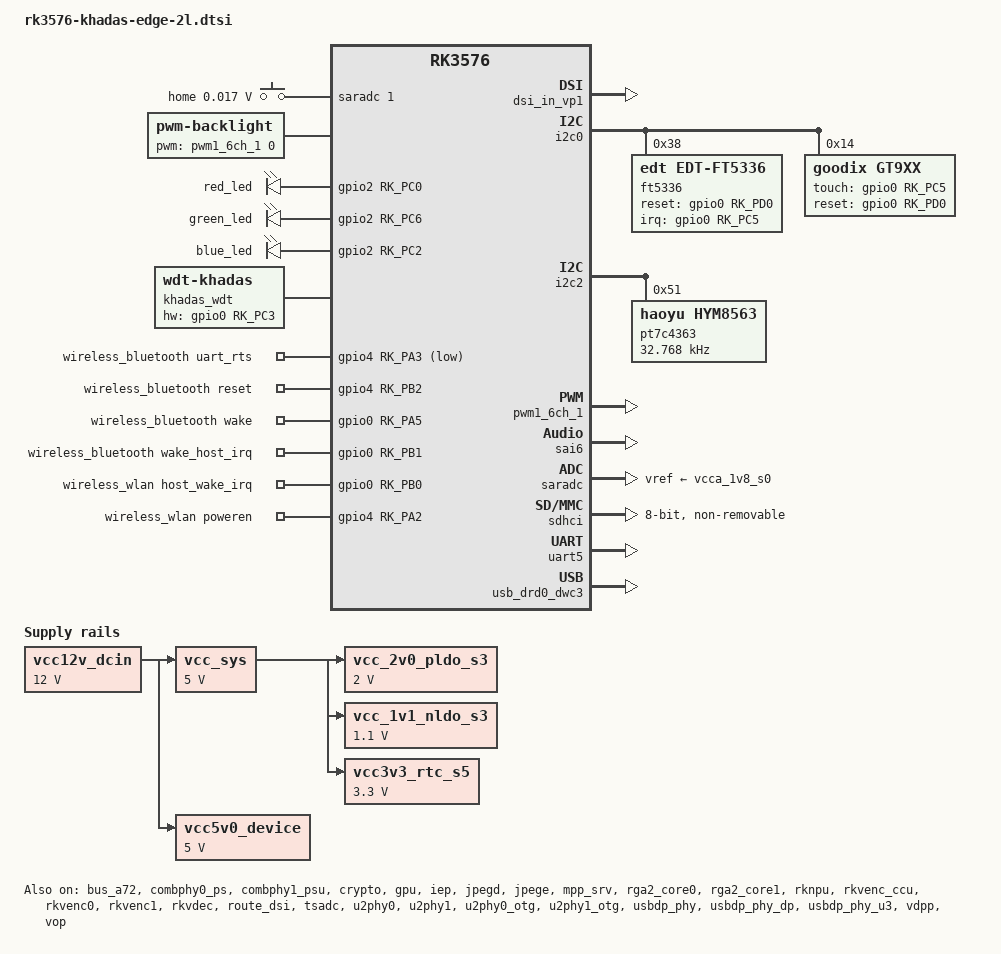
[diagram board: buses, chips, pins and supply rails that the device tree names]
// SPDX-License-Identifier: (GPL-2.0+ OR MIT)
/*
 * Copyright (c) 2024 Rockchip Electronics Co., Ltd.
 *
 */

#include <dt-bindings/gpio/gpio.h>
#include <dt-bindings/pwm/pwm.h>
#include <dt-bindings/pinctrl/rockchip.h>
#include <dt-bindings/input/rk-input.h>
#include <dt-bindings/display/drm_mipi_dsi.h>
#include <dt-bindings/display/rockchip_vop.h>
#include <dt-bindings/sensor-dev.h>
#include "rk3576-evb-input-keymap.dtsi"

/ {
	adc_keys: adc-keys {
		compatible = "adc-keys";
		io-channels = <&saradc 1>;
		io-channel-names = "buttons";
		keyup-threshold-microvolt = <1800000>;
		poll-interval = <100>;

		home-key {
			label = "home";
			linux,code = <KEY_HOMEPAGE>;
			press-threshold-microvolt = <17000>;
		};
	};

	backlight: backlight {
		compatible = "pwm-backlight";
		pwms = <&pwm1_6ch_1 0 25000 0>;
		brightness-levels = <
			  0  20  20  21  21  22  22  23
			 23  24  24  25  25  26  26  27
			 27  28  28  29  29  30  30  31
			 31  32  32  33  33  34  34  35
			 35  36  36  37  37  38  38  39
			 40  41  42  43  44  45  46  47
			 48  49  50  51  52  53  54  55
			 56  57  58  59  60  61  62  63
			 64  65  66  67  68  69  70  71
			 72  73  74  75  76  77  78  79
			 80  81  82  83  84  85  86  87
			 88  89  90  91  92  93  94  95
			 96  97  98  99 100 101 102 103
			104 105 106 107 108 109 110 111
			112 113 114 115 116 117 118 119
			120 121 122 123 124 125 126 127
			128 129 130 131 132 133 134 135
			136 137 138 139 140 141 142 143
			144 145 146 147 148 149 150 151
			152 153 154 155 156 157 158 159
			160 161 162 163 164 165 166 167
			168 169 170 171 172 173 174 175
			176 177 178 179 180 181 182 183
			184 185 186 187 188 189 190 191
			192 193 194 195 196 197 198 199
			200 201 202 203 204 205 206 207
			208 209 210 211 212 213 214 215
			216 217 218 219 220 221 222 223
			224 225 226 227 228 229 230 231
			232 233 234 235 236 237 238 239
			240 241 242 243 244 245 246 247
			248 249 250 251 252 253 254 255
		>;
		default-brightness-level = <200>;
	};

	dp0_sound: dp0-sound {
		status = "disabled";
		compatible = "rockchip,hdmi";
		rockchip,mclk-fs = <512>;
		rockchip,card-name = "rockchip-dp0";
		rockchip,cpu = <&spdif_tx3>;
		rockchip,codec = <&dp0 1>;
		rockchip,jack-det;
	};

	dp1_sound: dp1-sound {
		status = "disabled";
		compatible = "rockchip,hdmi";
		rockchip,mclk-fs = <512>;
		rockchip,card-name = "rockchip-dp1";
		rockchip,cpu = <&spdif_tx3>;
		rockchip,codec = <&dp1 1>;
		rockchip,jack-det;
	};

	dp2_sound: dp2-sound {
		status = "disabled";
		compatible = "rockchip,hdmi";
		rockchip,mclk-fs = <512>;
		rockchip,card-name = "rockchip-dp2";
		rockchip,cpu = <&spdif_tx3>;
		rockchip,codec = <&dp2 1>;
		rockchip,jack-det;
	};

	edp_sound: edp-sound {
		status = "disabled";
		compatible = "rockchip,hdmi";
		rockchip,mclk-fs = <128>;
		rockchip,card-name = "rockchip-edp";
		rockchip,cpu = <&sai6>;
		rockchip,codec = <&edp 0>;
	};

	hdmi_sound: hdmi-sound {
		compatible = "rockchip,hdmi";
		rockchip,mclk-fs = <128>;
		rockchip,card-name = "rockchip-hdmi";
		rockchip,cpu = <&sai6>;
		rockchip,codec = <&hdmi>;
		rockchip,jack-det;
	};

	leds {
		compatible = "gpio-leds";
		pinctrl-names = "default";

		red_led {
			gpios = <&gpio2 RK_PC0 GPIO_ACTIVE_HIGH>;
			label = "red_led";
			linux,default-trigger = "off";
			default-state = "on";
		};

		green_led {
			gpios = <&gpio2 RK_PC6 GPIO_ACTIVE_HIGH>;
			label = "green_led";
			linux,default-trigger = "off";
			default-state = "on";
		};

		blue_led {
			gpios = <&gpio2 RK_PC2 GPIO_ACTIVE_HIGH>;
			label = "blue_led";
			linux,default-trigger = "default-on";
			default-state = "on";
		};
	};

	khadas_wdt {
		compatible = "linux,wdt-khadas";
		status = "okay";
		hw_margin_ms = <500>;
		hw-gpios = <&gpio0 RK_PC3 GPIO_ACTIVE_HIGH>;
		pinctrl-names = "default";
		pinctrl-0 = <&wdt_gpio>;
	};

	test-power {
		status = "okay";
	};

	vcc12v_dcin: vcc12v-dcin {
		compatible = "regulator-fixed";
		regulator-name = "vcc12v_dcin";
		regulator-always-on;
		regulator-boot-on;
		regulator-min-microvolt = <12000000>;
		regulator-max-microvolt = <12000000>;
	};

	vcc_sys: vcc5v0-sys {
		compatible = "regulator-fixed";
		regulator-name = "vcc_sys";
		regulator-always-on;
		regulator-boot-on;
		regulator-min-microvolt = <5000000>;
		regulator-max-microvolt = <5000000>;
		vin-supply = <&vcc12v_dcin>;
	};

	vcc5v0_device: vcc5v0-device {
		compatible = "regulator-fixed";
		regulator-name = "vcc5v0_device";
		regulator-always-on;
		regulator-boot-on;
		regulator-min-microvolt = <5000000>;
		regulator-max-microvolt = <5000000>;
		vin-supply = <&vcc12v_dcin>;
	};

	vcc_2v0_pldo_s3: vcc-2v0-pldo-s3 {
		compatible = "regulator-fixed";
		regulator-name = "vcc_2v0_pldo_s3";
		regulator-boot-on;
		regulator-always-on;
		regulator-min-microvolt = <2000000>;
		regulator-max-microvolt = <2000000>;
		vin-supply = <&vcc_sys>;
	};

	vcc_1v1_nldo_s3: vcc-1v1-nldo-s3 {
		compatible = "regulator-fixed";
		regulator-name = "vcc_1v1_nldo_s3";
		regulator-boot-on;
		regulator-always-on;
		regulator-min-microvolt = <1100000>;
		regulator-max-microvolt = <1100000>;
		vin-supply = <&vcc_sys>;
	};

	vcc3v3_rtc_s5: vcc3v3-rtc-s5 {
		compatible = "regulator-fixed";
		regulator-name = "vcc3v3_rtc_s5";
		regulator-boot-on;
		regulator-always-on;
		regulator-min-microvolt = <3300000>;
		regulator-max-microvolt = <3300000>;
		vin-supply = <&vcc_sys>;
	};

	wireless_bluetooth: wireless-bluetooth {
		compatible = "bluetooth-platdata";
		uart_rts_gpios = <&gpio4 RK_PA3 GPIO_ACTIVE_LOW>;
		pinctrl-names = "default", "rts_gpio";
		pinctrl-0 = <&uart5m1_rtsn>, <&bt_gpio>;
		pinctrl-1 = <&uart5_gpios>;
		BT,reset_gpio    = <&gpio4 RK_PB2 GPIO_ACTIVE_HIGH>;
		BT,wake_gpio     = <&gpio0 RK_PA5 GPIO_ACTIVE_HIGH>;
		BT,wake_host_irq = <&gpio0 RK_PB1 GPIO_ACTIVE_HIGH>;
		status = "okay";
	};

	wireless_wlan: wireless-wlan {
		compatible = "wlan-platdata";
		wifi_chip_type = "ap6275p";
		pinctrl-names = "default";
		pinctrl-0 = <&wifi_host_wake_irq>, <&wifi_poweren_gpio>;
		WIFI,host_wake_irq = <&gpio0 RK_PB0 GPIO_ACTIVE_HIGH>;
		WIFI,poweren_gpio = <&gpio4 RK_PA2 GPIO_ACTIVE_HIGH>;
		status = "okay";
	};
};

&bus_a72 {
	bus-supply = <&vdd_logic_s0>;
	pvtm-supply = <&vdd_logic_s0>;
	status = "okay";
};

&combphy0_ps {
	status = "okay";
};

&combphy1_psu {
	status = "okay";
};

&cpu_l0 {
	cpu-supply = <&vdd_cpu_lit_s0>;
};

&cpu_b0 {
	cpu-supply = <&vdd_cpu_big_s0>;
};

&crypto {
	status = "okay";
};

&display_subsystem {
	clocks = <&hdptxphy_hdmi>;
	clock-names = "hdmi0_phy_pll";
};

&dsi {
	status = "disabled";
	//rockchip,lane-rate = <1000>;
	dsi_panel: panel@0 {
		status = "okay";
		compatible = "simple-panel-dsi";
		reg = <0>;
		backlight = <&backlight>;
		reset-delay-ms = <10>;
		enable-delay-ms = <10>;
		prepare-delay-ms = <10>;
		unprepare-delay-ms = <10>;
		disable-delay-ms = <60>;
		width-mm = <68>;
		height-mm = <121>;
		dsi,flags = <(MIPI_DSI_MODE_VIDEO | MIPI_DSI_MODE_VIDEO_BURST |
			      MIPI_DSI_MODE_LPM | MIPI_DSI_MODE_NO_EOT_PACKET)>;
		dsi,format = <MIPI_DSI_FMT_RGB888>;
		dsi,lanes  = <4>;
		panel-init-sequence = [
			15 00 02 FF 05
			15 00 02 FB 01
			15 64 02 C5 01
			15 00 02 FF EE
			15 00 02 FB 01
			15 00 02 1F 45
			15 00 02 24 4F
			15 00 02 38 C8
			15 00 02 39 27
			15 00 02 1E 77
			15 00 02 1D 0F
			15 00 02 7E 71
			15 00 02 7C 03
			15 00 02 FF 00
			15 00 02 FB 01
			15 00 02 35 01
			15 00 02 FF 01
			15 00 02 FB 01
			15 00 02 00 01
			15 00 02 01 55
			15 00 02 02 40
			15 00 02 05 40
			15 00 02 06 4A
			15 00 02 07 24
			15 00 02 08 0C
			15 00 02 0B 7D
			15 00 02 0C 7D
			15 00 02 0E B0
			15 00 02 0F AE
			15 00 02 11 10
			15 00 02 12 10
			15 00 02 13 03
			15 00 02 14 4A
			15 00 02 15 12
			15 00 02 16 12
			15 00 02 18 00
			15 00 02 19 77
			15 00 02 1A 55
			15 00 02 1B 13
			15 00 02 1C 00
			15 00 02 1D 00
			15 00 02 1E 13
			15 00 02 1F 00
			15 00 02 23 00
			15 00 02 24 00
			15 00 02 25 00
			15 00 02 26 00
			15 00 02 27 00
			15 00 02 28 00
			15 00 02 35 00
			15 00 02 66 00
			15 00 02 58 82
			15 00 02 59 02
			15 00 02 5A 02
			15 00 02 5B 02
			15 00 02 5C 82
			15 00 02 5D 82
			15 00 02 5E 02
			15 00 02 5F 02
			15 00 02 72 31
			15 00 02 FF 05
			15 00 02 FB 01
			15 00 02 00 01
			15 00 02 01 0B
			15 00 02 02 0C
			15 00 02 03 09
			15 00 02 04 0A
			15 00 02 05 00
			15 00 02 06 0F
			15 00 02 07 10
			15 00 02 08 00
			15 00 02 09 00
			15 00 02 0A 00
			15 00 02 0B 00
			15 00 02 0C 00
			15 00 02 0D 13
			15 00 02 0E 15
			15 00 02 0F 17
			15 00 02 10 01
			15 00 02 11 0B
			15 00 02 12 0C
			15 00 02 13 09
			15 00 02 14 0A
			15 00 02 15 00
			15 00 02 16 0F
			15 00 02 17 10
			15 00 02 18 00
			15 00 02 19 00
			15 00 02 1A 00
			15 00 02 1B 00
			15 00 02 1C 00
			15 00 02 1D 13
			15 00 02 1E 15
			15 00 02 1F 17
			15 00 02 20 00
			15 00 02 21 03
			15 00 02 22 01
			15 00 02 23 40
			15 00 02 24 40
			15 00 02 25 ED
			15 00 02 29 58
			15 00 02 2A 12
			15 00 02 2B 01
			15 00 02 4B 06
			15 00 02 4C 11
			15 00 02 4D 20
			15 00 02 4E 02
			15 00 02 4F 02
			15 00 02 50 20
			15 00 02 51 61
			15 00 02 52 01
			15 00 02 53 63
			15 00 02 54 77
			15 00 02 55 ED
			15 00 02 5B 00
			15 00 02 5C 00
			15 00 02 5D 00
			15 00 02 5E 00
			15 00 02 5F 15
			15 00 02 60 75
			15 00 02 61 00
			15 00 02 62 00
			15 00 02 63 00
			15 00 02 64 00
			15 00 02 65 00
			15 00 02 66 00
			15 00 02 67 00
			15 00 02 68 04
			15 00 02 69 00
			15 00 02 6A 00
			15 00 02 6C 40
			15 00 02 75 01
			15 00 02 76 01
			15 00 02 7A 80
			15 00 02 7B A3
			15 00 02 7C D8
			15 00 02 7D 60
			15 00 02 7F 15
			15 00 02 80 81
			15 00 02 83 05
			15 00 02 93 08
			15 00 02 94 10
			15 00 02 8A 00
			15 00 02 9B 0F
			15 00 02 EA FF
			15 00 02 EC 00
			15 00 02 FF 01
			15 00 02 FB 01
			15 00 02 75 00
			15 00 02 76 DF
			15 00 02 77 00
			15 00 02 78 E4
			15 00 02 79 00
			15 00 02 7A ED
			15 00 02 7B 00
			15 00 02 7C F6
			15 00 02 7D 00
			15 00 02 7E FF
			15 00 02 7F 01
			15 00 02 80 07
			15 00 02 81 01
			15 00 02 82 10
			15 00 02 83 01
			15 00 02 84 18
			15 00 02 85 01
			15 00 02 86 20
			15 00 02 87 01
			15 00 02 88 3D
			15 00 02 89 01
			15 00 02 8A 56
			15 00 02 8B 01
			15 00 02 8C 84
			15 00 02 8D 01
			15 00 02 8E AB
			15 00 02 8F 01
			15 00 02 90 EC
			15 00 02 91 02
			15 00 02 92 22
			15 00 02 93 02
			15 00 02 94 23
			15 00 02 95 02
			15 00 02 96 55
			15 00 02 97 02
			15 00 02 98 8B
			15 00 02 99 02
			15 00 02 9A AF
			15 00 02 9B 02
			15 00 02 9C DF
			15 00 02 9D 03
			15 00 02 9E 01
			15 00 02 9F 03
			15 00 02 A0 2C
			15 00 02 A2 03
			15 00 02 A3 39
			15 00 02 A4 03
			15 00 02 A5 47
			15 00 02 A6 03
			15 00 02 A7 56
			15 00 02 A9 03
			15 00 02 AA 66
			15 00 02 AB 03
			15 00 02 AC 76
			15 00 02 AD 03
			15 00 02 AE 85
			15 00 02 AF 03
			15 00 02 B0 90
			15 00 02 B1 03
			15 00 02 B2 CB
			15 00 02 B3 00
			15 00 02 B4 DF
			15 00 02 B5 00
			15 00 02 B6 E4
			15 00 02 B7 00
			15 00 02 B8 ED
			15 00 02 B9 00
			15 00 02 BA F6
			15 00 02 BB 00
			15 00 02 BC FF
			15 00 02 BD 01
			15 00 02 BE 07
			15 00 02 BF 01
			15 00 02 C0 10
			15 00 02 C1 01
			15 00 02 C2 18
			15 00 02 C3 01
			15 00 02 C4 20
			15 00 02 C5 01
			15 00 02 C6 3D
			15 00 02 C7 01
			15 00 02 C8 56
			15 00 02 C9 01
			15 00 02 CA 84
			15 00 02 CB 01
			15 00 02 CC AB
			15 00 02 CD 01
			15 00 02 CE EC
			15 00 02 CF 02
			15 00 02 D0 22
			15 00 02 D1 02
			15 00 02 D2 23
			15 00 02 D3 02
			15 00 02 D4 55
			15 00 02 D5 02
			15 00 02 D6 8B
			15 00 02 D7 02
			15 00 02 D8 AF
			15 00 02 D9 02
			15 00 02 DA DF
			15 00 02 DB 03
			15 00 02 DC 01
			15 00 02 DD 03
			15 00 02 DE 2C
			15 00 02 DF 03
			15 00 02 E0 39
			15 00 02 E1 03
			15 00 02 E2 47
			15 00 02 E3 03
			15 00 02 E4 56
			15 00 02 E5 03
			15 00 02 E6 66
			15 00 02 E7 03
			15 00 02 E8 76
			15 00 02 E9 03
			15 00 02 EA 85
			15 00 02 EB 03
			15 00 02 EC 90
			15 00 02 ED 03
			15 00 02 EE CB
			15 00 02 EF 00
			15 00 02 F0 BB
			15 00 02 F1 00
			15 00 02 F2 C0
			15 00 02 F3 00
			15 00 02 F4 CC
			15 00 02 F5 00
			15 00 02 F6 D6
			15 00 02 F7 00
			15 00 02 F8 E1
			15 00 02 F9 00
			15 00 02 FA EA
			15 00 02 FF 02
			15 00 02 FB 01
			15 00 02 00 00
			15 00 02 01 F4
			15 00 02 02 00
			15 00 02 03 EF
			15 00 02 04 01
			15 00 02 05 07
			15 00 02 06 01
			15 00 02 07 28
			15 00 02 08 01
			15 00 02 09 44
			15 00 02 0A 01
			15 00 02 0B 76
			15 00 02 0C 01
			15 00 02 0D A0
			15 00 02 0E 01
			15 00 02 0F E7
			15 00 02 10 02
			15 00 02 11 1F
			15 00 02 12 02
			15 00 02 13 22
			15 00 02 14 02
			15 00 02 15 54
			15 00 02 16 02
			15 00 02 17 8B
			15 00 02 18 02
			15 00 02 19 AF
			15 00 02 1A 02
			15 00 02 1B E0
			15 00 02 1C 03
			15 00 02 1D 01
			15 00 02 1E 03
			15 00 02 1F 2D
			15 00 02 20 03
			15 00 02 21 39
			15 00 02 22 03
			15 00 02 23 47
			15 00 02 24 03
			15 00 02 25 57
			15 00 02 26 03
			15 00 02 27 65
			15 00 02 28 03
			15 00 02 29 77
			15 00 02 2A 03
			15 00 02 2B 85
			15 00 02 2D 03
			15 00 02 2F 8F
			15 00 02 30 03
			15 00 02 31 CB
			15 00 02 32 00
			15 00 02 33 BB
			15 00 02 34 00
			15 00 02 35 C0
			15 00 02 36 00
			15 00 02 37 CC
			15 00 02 38 00
			15 00 02 39 D6
			15 00 02 3A 00
			15 00 02 3B E1
			15 00 02 3D 00
			15 00 02 3F EA
			15 00 02 40 00
			15 00 02 41 F4
			15 00 02 42 00
			15 00 02 43 FE
			15 00 02 44 01
			15 00 02 45 07
			15 00 02 46 01
			15 00 02 47 28
			15 00 02 48 01
			15 00 02 49 44
			15 00 02 4A 01
			15 00 02 4B 76
			15 00 02 4C 01
			15 00 02 4D A0
			15 00 02 4E 01
			15 00 02 4F E7
			15 00 02 50 02
			15 00 02 51 1F
			15 00 02 52 02
			15 00 02 53 22
			15 00 02 54 02
			15 00 02 55 54
			15 00 02 56 02
			15 00 02 58 8B
			15 00 02 59 02
			15 00 02 5A AF
			15 00 02 5B 02
			15 00 02 5C E0
			15 00 02 5D 03
			15 00 02 5E 01
			15 00 02 5F 03
			15 00 02 60 2D
			15 00 02 61 03
			15 00 02 62 39
			15 00 02 63 03
			15 00 02 64 47
			15 00 02 65 03
			15 00 02 66 57
			15 00 02 67 03
			15 00 02 68 65
			15 00 02 69 03
			15 00 02 6A 77
			15 00 02 6B 03
			15 00 02 6C 85
			15 00 02 6D 03
			15 00 02 6E 8F
			15 00 02 6F 03
			15 00 02 70 CB
			15 00 02 71 00
			15 00 02 72 00
			15 00 02 73 00
			15 00 02 74 21
			15 00 02 75 00
			15 00 02 76 4C
			15 00 02 77 00
			15 00 02 78 6B
			15 00 02 79 00
			15 00 02 7A 85
			15 00 02 7B 00
			15 00 02 7C 9A
			15 00 02 7D 00
			15 00 02 7E AD
			15 00 02 7F 00
			15 00 02 80 BE
			15 00 02 81 00
			15 00 02 82 CD
			15 00 02 83 01
			15 00 02 84 01
			15 00 02 85 01
			15 00 02 86 29
			15 00 02 87 01
			15 00 02 88 68
			15 00 02 89 01
			15 00 02 8A 98
			15 00 02 8B 01
			15 00 02 8C E5
			15 00 02 8D 02
			15 00 02 8E 1E
			15 00 02 8F 02
			15 00 02 90 30
			15 00 02 91 02
			15 00 02 92 52
			15 00 02 93 02
			15 00 02 94 88
			15 00 02 95 02
			15 00 02 96 AA
			15 00 02 97 02
			15 00 02 98 D7
			15 00 02 99 02
			15 00 02 9A F7
			15 00 02 9B 03
			15 00 02 9C 21
			15 00 02 9D 03
			15 00 02 9E 2E
			15 00 02 9F 03
			15 00 02 A0 3D
			15 00 02 A2 03
			15 00 02 A3 4C
			15 00 02 A4 03
			15 00 02 A5 5E
			15 00 02 A6 03
			15 00 02 A7 71
			15 00 02 A9 03
			15 00 02 AA 86
			15 00 02 AB 03
			15 00 02 AC 94
			15 00 02 AD 03
			15 00 02 AE FA
			15 00 02 AF 00
			15 00 02 B0 00
			15 00 02 B1 00
			15 00 02 B2 21
			15 00 02 B3 00
			15 00 02 B4 4C
			15 00 02 B5 00
			15 00 02 B6 6B
			15 00 02 B7 00
			15 00 02 B8 85
			15 00 02 B9 00
			15 00 02 BA 9A
			15 00 02 BB 00
			15 00 02 BC AD
			15 00 02 BD 00
			15 00 02 BE BE
			15 00 02 BF 00
			15 00 02 C0 CD
			15 00 02 C1 01
			15 00 02 C2 01
			15 00 02 C3 01
			15 00 02 C4 29
			15 00 02 C5 01
			15 00 02 C6 68
			15 00 02 C7 01
			15 00 02 C8 98
			15 00 02 C9 01
			15 00 02 CA E5
			15 00 02 CB 02
			15 00 02 CC 1E
			15 00 02 CD 02
			15 00 02 CE 20
			15 00 02 CF 02
			15 00 02 D0 52
			15 00 02 D1 02
			15 00 02 D2 88
			15 00 02 D3 02
			15 00 02 D4 AA
			15 00 02 D5 02
			15 00 02 D6 D7
			15 00 02 D7 02
			15 00 02 D8 F7
			15 00 02 D9 03
			15 00 02 DA 21
			15 00 02 DB 03
			15 00 02 DC 2E
			15 00 02 DD 03
			15 00 02 DE 3D
			15 00 02 DF 03
			15 00 02 E0 4C
			15 00 02 E1 03
			15 00 02 E2 5E
			15 00 02 E3 03
			15 00 02 E4 71
			15 00 02 E5 03
			15 00 02 E6 86
			15 00 02 E7 03
			15 00 02 E8 94
			15 00 02 E9 03
			15 00 02 EA FA
			15 00 02 FF 01
			15 00 02 FB 01
			15 00 02 FF 02
			15 00 02 FB 01
			15 00 02 FF 04
			15 00 02 FB 01
			15 00 02 FF 00
			15 00 02 D3 05
			15 00 02 D4 04
			05 78 01 11
			15 00 02 FF 00
			15 00 02 35 00
			05 0A 01 29
		];

		panel-init-sequence2 = [
			39 00 04 B9 FF 83 99
			39 00 05 BA 63 23 68 CF
			15 00 02 D2 55
			39 00 10 B1 02 04 70 90 01 32 33 11 11 4D 57 56 73 02 02
			39 00 0c B2 00 80 80 AE 0A 0E 75 11 00 00 00
			39 00 2f B4 00 FF 04 A4 02 A0 00 00 10 00 00 02 00 24 02 04 0A 21 03 00 00 08 A6 88 04 A4 02 A0 00 00 10 00 00 02 00 24 02 04 0A 00 00 08 A6 00 08 11
			39 00 22 D3 00 00 00 00 00 00 18 18 32 10 09 00 09 32 10 00 00 00 00 00 00 00 00 11 00 02 02 03 00 00 00 0A 40
			39 00 21 D5 18 18 18 18 21 20 18 18 19 19 19 19 18 18 18 18 03 02 01 00 2F 2F 30 30 31 31 18 18 18 18 18 18
			39 00 21 D6 18 18 18 18 20 21 19 19 18 18 19 19 18 18 18 18 00 01 02 03 2F 2F 30 30 31 31 18 18 18 18 18 18
			39 00 09 D8 0A BE FA A0 0A BE FA A0
			15 00 02 BD 01
			39 00 09 D8 0F FF FF E0 0F FF FF E0
			15 00 02 BD 02
			39 00 09 D8 0F FF FF E0 0F FF FF E0
			15 00 02 BD 00
			39 00 37 E0 01 35 41 3B 79 81 8C 85 8E 95 9B A0 A4 AB B1 B3 B7 C5 BD C5 B6 C2 C2 62 5D 66 73 01 35 41 3B 79 81 8C 85 8E 95 9B A0 A4 AB B1 B3 B7 B5 BD C5 B6 C2 C2 62 5D 66 73
			39 00 03 B6 97 97
			15 00 02 CC C8
			39 00 05 BF 40 41 50 19
			39 00 03 C6 FF F9
			39 00 03 C0 25 5A
			05 78 01 11
			05 14 01 29
		];

		panel-init-sequence3 = [
			15 00 02 B0 05
			15 00 02 C0 01
			15 00 02 C2 01
			15 00 02 D9 01
			15 00 02 DB 01
			15 00 02 B0 00
			15 00 02 B6 03
			15 00 02 BD 62
			15 00 02 C2 16
			15 00 02 C3 02
			15 00 02 C4 16
			15 00 02 C5 02
			15 00 02 B0 01
			15 00 02 E0 0F
			15 00 02 E1 0F
			15 00 02 DC 10
			15 00 02 DD 10
			15 00 02 CC 0F
			15 00 02 CD 0F
			15 00 02 C8 10
			15 00 02 C9 10
			15 00 02 B0 03
			15 00 02 C5 2C
			15 00 02 DE 2C
			15 00 02 CA 42
			15 00 02 D6 88
			15 00 02 D7 08
			15 00 02 D2 06
			15 00 02 D3 06
			15 00 02 B0 05
			15 00 02 B3 52
			15 00 02 BC 20
			15 00 02 B0 06
			15 00 02 B8 A5
			15 00 02 C0 A5
			15 00 02 C7 0F
			15 00 02 D5 32
			15 00 02 B0 02
			15 00 02 C0 00
			15 00 02 C1 14
			15 00 02 C2 16
			15 00 02 C3 24
			15 00 02 C4 25
			15 00 02 C5 31
			15 00 02 C6 2A
			15 00 02 C7 2D
			15 00 02 C8 33
			15 00 02 C9 37
			15 00 02 CA 3F
			15 00 02 CB 3F
			15 00 02 CC 3F
			15 00 02 CD 2D
			15 00 02 CE 2E
			15 00 02 CF 29
			15 00 02 D0 04
			15 00 02 D2 00
			15 00 02 D3 14
			15 00 02 D4 14
			15 00 02 D5 26
			15 00 02 D6 2D
			15 00 02 D7 31
			15 00 02 D8 38
			15 00 02 D9 3D
			15 00 02 DA 3F
			15 00 02 DB 3F
			15 00 02 DC 3F
			15 00 02 DD 3F
			15 00 02 DE 3F
			15 00 02 DF 38
			15 00 02 E0 35
			15 00 02 E1 2D
			15 00 02 E2 0A
			15 00 02 B0 06
			15 00 02 B8 A5
			15 00 02 BC 33
			15 00 02 B0 07
			15 00 02 B1 00
			15 00 02 B2 04
			15 00 02 B3 0D
			15 00 02 B4 31
			15 00 02 B5 4F
			15 00 02 B6 6F
			15 00 02 B7 A1
			15 00 02 B8 E5
			15 00 02 B9 5B
			15 00 02 BA C1
			15 00 02 BB 54
			15 00 02 BC BB
			15 00 02 BD BE
			15 00 02 BE 12
			15 00 02 BF 69
			15 00 02 C0 94
			15 00 02 C1 B6
			15 00 02 C2 C8
			15 00 02 C3 DB
			15 00 02 C4 E8
			15 00 02 C5 F3
			15 00 02 C6 F9
			15 00 02 C7 FB
			15 00 02 C8 FC
			15 00 02 C9 00
			15 00 02 CA 00
			15 00 02 CB 5A
			15 00 02 CC BF
			15 00 02 CD FF
			15 00 02 CE FF
			15 00 02 B0 08
			15 00 02 B1 00
			15 00 02 B2 04
			15 00 02 B3 0D
			15 00 02 B4 31
			15 00 02 B5 4F
			15 00 02 B6 6F
			15 00 02 B7 A1
			15 00 02 B8 E5
			15 00 02 B9 5B
			15 00 02 BA C1
			15 00 02 BB 54
			15 00 02 BC BB
			15 00 02 BD BE
			15 00 02 BE 12
			15 00 02 BF 69
			15 00 02 C0 94
			15 00 02 C1 B6
			15 00 02 C2 C8
			15 00 02 C3 DB
			15 00 02 C4 E8
			15 00 02 C5 F3
			15 00 02 C6 F9
			15 00 02 C7 FB
			15 00 02 C8 FC
			15 00 02 C9 00
			15 00 02 CA 00
			15 00 02 CB 5A
			15 00 02 CC BF
			15 00 02 CD FF
			15 00 02 CE FF
			15 00 02 B0 09
			15 00 02 B1 00
			15 00 02 B2 04
			15 00 02 B3 0D
			15 00 02 B4 31
			15 00 02 B5 4F
			15 00 02 B6 6F
			15 00 02 B7 A1
			15 00 02 B8 E5
			15 00 02 B9 5B
			15 00 02 BA C1
			15 00 02 BB 54
			15 00 02 BC BB
			15 00 02 BD BE
			15 00 02 BE 12
			15 00 02 BF 69
			15 00 02 C0 94
			15 00 02 C1 B6
			15 00 02 C2 C8
			15 00 02 C3 DB
			15 00 02 C4 E8
			15 00 02 C5 F3
			15 00 02 C6 F9
			15 00 02 C7 FB
			15 00 02 C8 FC
			15 00 02 C9 00
			15 00 02 CA 00
			15 00 02 CB 5A
			15 00 02 CC BF
			15 00 02 CD FF
			15 00 02 CE FF
			15 00 02 B0 0A
			15 00 02 B1 00
			15 00 02 B2 04
			15 00 02 B3 0D
			15 00 02 B4 31
			15 00 02 B5 4F
			15 00 02 B6 6F
			15 00 02 B7 A1
			15 00 02 B8 E5
			15 00 02 B9 5B
			15 00 02 BA C1
			15 00 02 BB 54
			15 00 02 BC BB
			15 00 02 BD BE
			15 00 02 BE 12
			15 00 02 BF 69
			15 00 02 C0 94
			15 00 02 C1 B6
			15 00 02 C2 C8
			15 00 02 C3 DB
			15 00 02 C4 E8
			15 00 02 C5 F3
			15 00 02 C6 F9
			15 00 02 C7 FB
			15 00 02 C8 FC
			15 00 02 C9 00
			15 00 02 CA 00
			15 00 02 CB 5A
			15 00 02 CC BF
			15 00 02 CD FF
			15 00 02 CE FF
			15 00 02 B0 0B
			15 00 02 B1 00
			15 00 02 B2 04
			15 00 02 B3 0D
			15 00 02 B4 31
			15 00 02 B5 4F
			15 00 02 B6 6F
			15 00 02 B7 A1
			15 00 02 B8 E5
			15 00 02 B9 5B
			15 00 02 BA C1
			15 00 02 BB 54
			15 00 02 BC BB
			15 00 02 BD BE
			15 00 02 BE 12
			15 00 02 BF 69
			15 00 02 C0 94
			15 00 02 C1 B6
			15 00 02 C2 C8
			15 00 02 C3 DB
			15 00 02 C4 E8
			15 00 02 C5 F3
			15 00 02 C6 F9
			15 00 02 C7 FB
			15 00 02 C8 FC
			15 00 02 C9 00
			15 00 02 CA 00
			15 00 02 CB 5A
			15 00 02 CC BF
			15 00 02 CD FF
			15 00 02 CE FF
			15 00 02 B0 0C
			15 00 02 B1 00
			15 00 02 B2 04
			15 00 02 B3 0D
			15 00 02 B4 31
			15 00 02 B5 4F
			15 00 02 B6 6F
			15 00 02 B7 A1
			15 00 02 B8 E5
			15 00 02 B9 5B
			15 00 02 BA C1
			15 00 02 BB 54
			15 00 02 BC BB
			15 00 02 BD BE
			15 00 02 BE 12
			15 00 02 BF 69
			15 00 02 C0 94
			15 00 02 C1 B6
			15 00 02 C2 C8
			15 00 02 C3 DB
			15 00 02 C4 E8
			15 00 02 C5 F3
			15 00 02 C6 F9
			15 00 02 C7 FB
			15 00 02 C8 FC
			15 00 02 C9 00
			15 00 02 CA 00
			15 00 02 CB 5A
			15 00 02 CC BF
			15 00 02 CD FF
			15 00 02 CE FF
			15 00 02 B0 00
			05 78 01 11
			05 14 01 29
		];

		panel-init-sequence4 = [
			15 00 02 41 5A
			39 00 03 41 5A 03
			15 00 02 80 85
			39 00 03 41 5A 08
			39 00 05 80 82 00 82 00
			39 00 03 41 5A 09
			39 00 11 80 1A 01 AB 93 A5 97 59 2A B1 06 00 00 80 BF 85 10
			39 00 11 90 42 44 84 14 C6 23 9A 19 C0 23 44 C2 07 C0 27 00
			39 00 11 A0 80 90 20 AA 00 04 55 55 05 00 1F 0D 42 00 FE FF
			39 00 11 B0 03 CE F6 00 3B 01 3B 01 00 00 00 41 25 00 4A 00
			39 00 11 C0 00 00 00 00 00 00 00 00 10 04 02 00 07 00 08 18
			39 00 03 D0 00 00
			39 00 03 41 5A 0A
			39 00 11 80 AF AF D4 30 3B 2B 39 42 4C 5C 69 6A 77 79 8E 74
			39 00 11 90 60 60 55 4D 42 33 2A 22 13 0D 0A 30 3B 2B 39 42
			39 00 11 A0 4C 5C 69 6A 77 79 8E 74 60 60 55 4D 42 33 2A 22
			39 00 04 B0 13 0D 0A
			39 00 03 41 5A 0B
			39 00 11 80 00 00 50 B5 C5 AC 00 00 A0 6A 8B A9 AE 22 02 00
			39 00 11 90 EF D8 B8 F7 25 70 E0 08 11 02 40 13 4F 4D 3C 35
			39 00 09 A0 F1 A4 06 FF FF 00 03 00
			39 00 03 41 5A 0C
			39 00 11 80 FD 68 58 02 BC 3F 41 07 00 00 56 01 00 55 61 15
			39 00 11 90 55 51 15 56 01 00 56 01 00 55 61 15 55 51 15 56
			39 00 11 A0 B1 84 01 00 00 00 00 00 00 40 94 02 00 00 00 30
			39 00 11 B0 28 15 80 04 00 18 00 00 00 30 0A 00 00 00 00 00
			39 00 08 C0 00 01 05 C2 B0 00 00
			39 00 03 41 5A 0D
			39 00 11 80 08 00 00 28 02 00 04 12 00 08 02 77 02 4A 10 F0
			39 00 07 90 00 02 58 16 04 A1
			39 00 03 41 5A 0E
			39 00 11 80 FF 81 68 EC 26 FD 22 00 55 55 55 55 05 5A 5A 80
			39 00 07 90 01 00 00 60 01 00
			39 00 03 41 5A 0F
			39 00 11 80 51 F5 40 24 00 00 90 04 0C 00 20 04 10 00 A8 C3
			39 00 11 90 26 D0 10 80 07 14 08 A0 05 5A 10 00 00 10 84 10
			39 00 11 A0 30 04 43 B3 60 C0 4A 0B 5A 71 22 80 19 4A 00 20
			39 00 11 B0 27 9E 01 C0 19 7A 21 14 00 40 30 E0 00 2D D0 82
			39 00 11 C0 00 00 60 18 63 D0 A0 0D 9A 21 02 10 62 84 28 03
			39 00 11 D0 8A 88 88 48 92 09 0F 15 1E E0 31 06 04 02 14 04
			39 00 11 E0 10 22 22 7D 67 08 33 64 0C B1 2C 2F 64 40 41 00
			39 00 10 F0 00 0B 12 04 F5 FF FF 3F 00 00 15 40 14 00 00
			39 00 03 41 5A 10
			39 00 11 80 00 00 03 E7 8F 0B 00 3C 80 01 6A 0C 18 C4 20 C5
			39 00 11 90 1C 94 D4 62 CD 3D F8 03 3F F0 03 3F 00 FF FF FF
			39 00 03 A0 81 00
			39 00 03 41 5A 11
			39 00 08 80 00 00 00 00 00 00 00
			39 00 03 41 5A 12
			39 00 11 80 00 00 00 00 00 00 00 00 00 00 00 00 00 00 00 00
			39 00 11 90 00 10 00 00 00 00 00 00 00 00 00 00 00 00 00 00
			39 00 11 A0 00 00 00 00 00 00 2D 23 05 FB 00 2D 23 05 FB 00
			39 00 08 B0 01 00 00 00 00 00 00
			39 00 03 41 5A 13
			39 00 11 80 00 08 80 15 00 90 10 18 3E 10 00 D6 03 04 18 00
			39 00 11 90 70 88 30 90 32 70 3E 97 8B 39 30 C4 09 C4 09 C4
			39 00 11 A0 89 4F DC 45 E0 09 C4 09 C4 09 80 02 00 00 00 00
			39 00 11 B0 00 00 00 00 00 00 DB 01 31 75 B9 42 86 CA 31 75
			39 00 11 C0 B9 42 86 CA 00 00 00 00 0C 60 00 24 18 00 09 06
			39 00 11 D0 40 82 01 90 60 00 24 D0 01 09 74 40 02 1D 90 40
			39 00 11 E0 07 24 D0 01 09 1E 46 1E 46 00 00 20 C5 0F 00 C0
			39 00 0d F0 10 40 26 4E 46 02 C8 20 80 0C 00 00
			39 00 03 41 5A 14
			39 00 11 80 01 02 40 2C 99 DF EF F7 53 8C 01 00 00 C0 83 D8
			39 00 11 90 90 4C 12 10 17 92 49 02 72 45 32 49 80 66 98 CF
			39 00 11 A0 09 D0 0C BF 1F 01 9A E1 F7 23 00 80 07 00 00 00
			39 00 11 B0 00 00 00 00 00 00 00 00 00 00 00 00 80 84 07 84
			39 00 11 C0 07 05 00 30 18 0C CF 00 C5 78 14 C5 00 F4 04 50
			39 00 11 D0 8C 47 51 0C 40 4F 01 C5 78 14 C5 00 F4 24 50 8C
			39 00 11 E0 47 51 0C 40 CF 04 C5 78 14 C5 00 F4 3C 50 8C 47
			39 00 11 F0 51 0C 40 CF 02 C5 78 14 C5 00 F4 1C 50 8C 47 51
			39 00 03 41 5A 15
			39 00 11 80 0C 40 45 80 DF 0F 00 00 00 00 00 00 00 00 00 00
			39 00 11 90 00 00 00 00 00 00 00 00 00 C0 D1 03 0A 1E 8F 00
			39 00 11 A0 00 1E A4 84 52 AB 0D 42 60 5E 00 00 00 20 08 81
			39 00 11 B0 39 00 00 00 00 00 00 00 00 00 00 00 00 00 00 00
			39 00 11 C0 00 40 00 00 00 00 00 00 00 20 1F 40 38 06 50 28
			39 00 11 D0 0A 0C 39 AE EB 5A D3 6C 1D 47 51 0C 43 10 24 A9
			39 00 11 E0 6D 29 2A 04 39 AE EB 5A D3 6C 01 80 20 10 84 61
			39 00 11 F0 20 A8 6D 29 0A 0C 39 AE EB 5A D3 6C 19 06 41 08
			39 00 03 41 5A 16
			39 00 11 80 02 00 20 A8 6D 29 2A 04 39 AE EB 5A D3 6C 05 C1
			39 00 11 90 30 14 C5 71 24 A9 6D 01 0A 0A 00 00 00 00 00 00
			39 00 11 A0 00 00 00 00 00 00 00 00 00 00 00 00 C0 1F E1 01
			39 00 11 B0 28 02 00 00 00 00 00 00 00 00 04 00 00 00 00 00
			39 00 11 C0 00 00 00 00 00 00 02 06 00 00 00 00 00 00 02 00
			39 00 11 D0 00 00 00 00 00 00 00 00 04 00 00 00 00 00 00 00
			39 00 11 E0 00 00 00 00 01 00 00 00 00 00 00 00 00 00 00 00
			39 00 11 F0 00 04 00 00 00 00 00 00 00 00 00 20 00 00 00 00
			39 00 03 41 5A 17
			39 00 11 80 00 00 00 00 00 04 00 00 00 00 00 00 00 00 00 20
			39 00 11 90 00 00 00 00 00 00 00 00 00 10 00 00 00 00 00 00
			39 00 11 A0 00 00 00 00 00 00 00 10 00 00 00 00 00 00 00 00
			39 00 11 B0 40 00 00 00 00 00 00 00 00 00 01 00 00 00 00 00
			39 00 11 C0 00 00 00 00 10 00 00 00 00 00 00 00 00 00 00 00
			39 00 07 D0 00 01 00 00 00 00
			39 00 03 41 5A 18
			39 00 11 80 7F 7F FE FE FE FE FE FE FE FE FE FE D4 7F D4 D4
			39 00 11 90 D4 D4 D4 D4 D4 D4 D4 D4 AA AA AA AA AA AA AA AA
			39 00 11 A0 AA AA AA AA 7F 7F 7F 7F 7F 7F 7F 7F 7F 7F 7F 7F
			39 00 11 B0 7C 83 79 86 79 86 79 86 79 86 79 86 7A 83 7A 85
			39 00 11 C0 7A 85 7A 85 7A 85 7A 85 7B 84 7B 84 7B 84 7B 84
			39 00 11 D0 7B 84 7B 84 7C 83 7C 83 7C 83 7C 83 7C 83 7C 83
			39 00 11 E0 FE 7F 7F FE FE FE FE FE FE FE FE FE FE D4 7F D4
			39 00 11 F0 D4 D4 D4 D4 D4 D4 D4 D4 D4 AA AA AA AA AA AA AA
			39 00 03 41 5A 19
			39 00 11 80 AA AA AA AA AA 7F 7F 7F 7F 7F 7F 7F 7F 7F 7F 7F
			39 00 11 90 7F 7C 83 79 86 79 86 79 86 79 86 79 86 7A 83 7A
			39 00 11 A0 85 7A 85 7A 85 7A 85 7A 85 7B 84 7B 84 7B 84 7B
			39 00 11 B0 84 7B 84 7B 84 7C 83 7C 83 7C 83 7C 83 7C 83 7C
			39 00 11 C0 83 7F 04 FF 1E 00 08 10 18 20 28 30 38 FC 00 04
			39 00 0c D0 20 00 01 08 40 00 02 10 80 00 FC
			39 00 03 41 5A 1A
			39 00 11 80 F0 D9 C8 BA AF A6 9E 98 92 8D 88 84 00 60 F6 CF
			39 00 11 90 FC 6F F6 EF CF AF 5F 55 00 F8 00 F8 00 F8 AD 8D
			39 00 11 A0 73 60 53 4A 43 7F 78 10 A0 3F 00 00 00 00 00 00
			39 00 11 B0 00 00 00 00 00 00 00 00 00 00 00 00 00 00 00 00
			39 00 09 C0 00 00 00 00 00 00 00 00
			39 00 03 41 5A 1C
			39 00 11 80 00 04 08 0C 00 10 14 18 1C 00 20 28 30 38 00 40
			39 00 11 90 48 50 58 00 60 68 70 78 00 80 88 90 98 00 A0 A8
			39 00 11 A0 B0 B8 00 C0 C8 D0 D8 00 E0 E8 F0 F8 00 FC FE FF
			39 00 11 B0 00 00 04 08 0C 00 10 14 18 1C 00 20 28 30 38 00
			39 00 11 C0 40 48 50 58 00 60 68 70 78 00 80 88 90 98 00 A0
			39 00 11 D0 A8 B0 B8 00 C0 C8 D0 D8 00 E0 E8 F0 F8 00 FC FE
			39 00 11 E0 FF 00 00 04 08 0C 00 10 14 18 1C 00 20 28 30 38
			39 00 11 F0 00 40 48 50 58 00 60 68 70 78 00 80 88 90 98 00
			39 00 03 41 5A 1D
			39 00 11 80 A0 A8 B0 B8 00 C0 C8 D0 D8 00 E0 E8 F0 F8 00 FC
			39 00 05 90 FE FF 00 00
			39 00 03 41 5A 1F
			39 00 11 80 5A 0F 70 09 28 30 38 40 48 50 58 60 20 30 38 40
			39 00 11 90 48 50 58 60 20 28 38 40 48 50 58 60 20 28 30 40
			39 00 11 A0 48 50 58 60 20 28 30 38 48 50 58 60 20 28 30 38
			39 00 11 B0 40 50 58 60 20 28 30 38 40 48 58 60 20 28 30 38
			39 00 11 C0 40 48 50 60 20 28 30 38 40 48 50 58 FF 5A 1E 20
			39 00 0d D0 00 02 20 00 02 20 00 02 20 00 02 FE
			39 00 03 41 5A 20
			39 00 11 80 44 73 03 00 CA F3 FF 6B 10 08 02 08 03 41 18 30
			39 00 11 90 18 44 E1 40 E1 20 30 18 C8 21 41 01 39 13 44 42
			39 00 11 A0 91 50 28 14 0A 85 03 D2 B0 80 36 7F D0 1F 12 E0
			39 00 11 B0 18 36 1B 11 04 20 02 D0 80 B3 21 38 20 18 88 03
			39 00 11 C0 82 01 4D 70 40 30 8D 0D A4 A2 00 80 04 38 00 50
			39 00 11 D0 80 13 E0 00 14 C0 70 40 00 E0 81 00 00 28 0E 06
			39 00 11 E0 43 55 55 55 55 55 D5 CC CC CC CC CC 4C 08 82 C6
			39 00 11 F0 E0 01 00 00 00 21 42 88 00 00 00 00 00 00 24 20
			39 00 03 41 5A 21
			39 00 11 80 04 41 06 00 00 00 00 00 00 49 00 00 49 00 00 00
			39 00 11 90 00 00 00 85 11 0C 00 00 40 00 00 00 00 16 00 A5
			39 00 11 A0 00 08 08 15 10 D1 B6 45 92 8A 20 A2 6D 0B 00 54
			39 00 11 B0 40 44 DB 16 00 48 92 24 09 E0 0F 80 55 30 01 10
			39 00 11 C0 01 42 82 11 20 02 10 10 01 08 88 00 04 44 00 02
			39 00 11 D0 22 00 04 91 80 1F 00 40 40 04 00 00 00 18 10 16
			39 00 03 E0 10 00
			39 00 03 41 5A 22
			39 00 11 80 29 D3 00 55 55 55 55 55 55 55 55 55 55 55 1F 70
			39 00 04 90 F0 00 00
			39 00 03 41 5A 23
			39 00 11 80 09 01 02 05 00 05 04 00 00 00 00 00 00 00 00 00
			39 00 0a 90 00 FF 1F 20 00 01 00 00 FE
			39 00 03 41 5A 24
			39 00 11 80 00 03 00 FF FF 66 00 00 00 00 00 00 00 00 3B BE
			39 00 0f 90 5A A5 5A 00 00 00 00 22 22 3A 22 00 00 00
			39 00 03 41 5A 24
			15 00 02 90 A5
			39 00 03 41 5A 2F
			15 00 02 4C 03
			15 00 02 09 01
			39 00 03 51 ff 0f
			15 00 02 53 24
			15 00 02 55 00
			05 78 01 11
			05 14 01 29
		];

		panel-exit-sequence = [
			05 05 01 28
			05 78 01 10
		];

		disp_timings0: display-timings {
			native-mode = <&dsi0_timing0>;
			dsi0_timing0: timing0 {
				clock-frequency = <152198100>;
				hactive = <1080>;
				vactive = <1920>;
				hfront-porch = <104>;
				hsync-len = <4>;
				hback-porch = <127>;
				vfront-porch = <4>;
				vsync-len = <3>;
				vback-porch = <2>;
				hsync-active = <0>;
				vsync-active = <0>;
				de-active = <0>;
				pixelclk-active = <0>;
			};
		};

		disp_timings01: display-timings1 {
			native-mode = <&dsi0_timing01>;
			dsi0_timing01: timing01 {
				clock-frequency = <152350000>;
				hactive = <1920>;
				vactive = <1200>;
				hfront-porch = <110>;
				hsync-len = <4>;
				hback-porch = <32>;
				vfront-porch = <11>;
				vsync-len = <4>;
				vback-porch = <14>;
				hsync-active = <0>;
				vsync-active = <0>;
				de-active = <0>;
				pixelclk-active = <0>;
			};
		};

		disp_timings02: display-timings2 {
			native-mode = <&dsi0_timing02>;
			dsi0_timing02: timing02 {
				clock-frequency = <152200000>;
				hactive = <1080>;
				vactive = <1920>;
				hfront-porch = <104>;
				hsync-len = <6>;
				hback-porch = <127>;
				vfront-porch = <12>;
				vsync-len = <6>;
				vback-porch = <10>;
				hsync-active = <0>;
				vsync-active = <0>;
				de-active = <0>;
				pixelclk-active = <0>;
			};
		};

		disp_timings03: display-timings3 {
			native-mode = <&dsi0_timing03>;
			dsi0_timing03: timing01 {
				clock-frequency = <153976320>;
				hactive = <1200>;
				vactive = <1920>;
				hfront-porch = <38>;
				hsync-len = <24>;
				hback-porch = <50>;
				vfront-porch = <16>;
				vsync-len = <4>;
				vback-porch = <16>;
				hsync-active = <0>;
				vsync-active = <0>;
				de-active = <0>;
				pixelclk-active = <0>;
			};
		};

		disp_timings04: display-timings4 {
			native-mode = <&dsi0_timing04>;
			dsi0_timing04: timing01 {
				clock-frequency = <163000000>;
				hactive = <1200>;
				vactive = <1920>;
				hfront-porch = <32>;
				hsync-len = <20>;
				hback-porch = <10>;
				vfront-porch = <194>;
				vsync-len = <6>;
				vback-porch = <32>;
				hsync-active = <0>;
				vsync-active = <0>;
				de-active = <0>;
				pixelclk-active = <0>;
			};
		};

		ports {
			#address-cells = <1>;
			#size-cells = <0>;

			port@0 {
				reg = <0>;
				panel_in_dsi: endpoint {
					remote-endpoint = <&dsi_out_panel>;
				};
			};
		};
	};

	ports {
		#address-cells = <1>;
		#size-cells = <0>;

		port@1 {
			reg = <1>;
			dsi_out_panel: endpoint {
				remote-endpoint = <&panel_in_dsi>;
			};
		};
	};

};

&dsi_in_vp0 {
	status = "disabled";
};

&dsi_in_vp1 {
	status = "okay";
};

&dsi_in_vp2 {
	status = "disabled";
};

&dsi_in_vopl {
	status = "disabled";
};

&gpu {
	mali-supply = <&vdd_gpu_s0>;
	status = "okay";
};

&i2c0 {
	pinctrl-0 = <&i2c0m1_xfer>;
	status = "okay";

	ft5336@38 {
		compatible = "edt,edt-ft5336", "ft5x06";
		reg = <0x38>;
		interrupt-parent = <&gpio0>;
		interrupts = <RK_PC5 IRQ_TYPE_EDGE_FALLING>;
		reset-gpio = <&gpio0 RK_PD0 GPIO_ACTIVE_HIGH>;
		pinctrl-names = "default";
		pinctrl-0 = <&tp_rst_gpio>;
		status = "okay";
	};

	gt9xx: gt9xx@14 {
		compatible = "goodix,gt9xx";
		reg = <0x14>;
		touch-gpio = <&gpio0 RK_PC5 IRQ_TYPE_LEVEL_LOW>;
		reset-gpio = <&gpio0 RK_PD0 GPIO_ACTIVE_HIGH>;
		max-x = <1920>;
		max-y = <1200>;
		tp-size = <89>;
		wakeup-source = <1>;
		status = "okay";
	};
};

&i2c2 {
	status = "okay";

	pt7c4363: pt7c4363@51 {
		compatible = "haoyu,hym8563";
		reg = <0x51>;
		#clock-cells = <0>;
		clock-frequency = <32768>;
		clock-output-names = "pt7c4363";
		wakeup-source;
	};
};

&iep {
	status = "okay";
};

&iep_mmu {
	status = "okay";
};

&jpegd {
	status = "okay";
};

&jpege {
	status = "okay";
};

&jpeg_mmu {
	status = "okay";
};

&mpp_srv {
	status = "okay";
};

&pinctrl {
	touch {
		touch_gpio: touch-gpio {
			rockchip,pins =
				<0 RK_PD0 RK_FUNC_GPIO &pcfg_pull_up>,
				<0 RK_PC5 RK_FUNC_GPIO &pcfg_pull_up>;
		};
	};

	wireless-bluetooth {
		uart5_gpios: uart5-gpios {
			rockchip,pins = <4 RK_PA3 RK_FUNC_GPIO &pcfg_pull_none>;
		};

		bt_gpio: bt-gpio {
			rockchip,pins =
				<4 RK_PB2 RK_FUNC_GPIO &pcfg_pull_none>,
				<0 RK_PA5 RK_FUNC_GPIO &pcfg_pull_up>,
				<0 RK_PB1 RK_FUNC_GPIO &pcfg_pull_down>;
		};
	};

	wireless-wlan {
		wifi_host_wake_irq: wifi-host-wake-irq {
			rockchip,pins = <0 RK_PB0 RK_FUNC_GPIO &pcfg_pull_down>;
		};

		wifi_poweren_gpio: wifi-poweren-gpio {
			rockchip,pins = <4 RK_PA2 RK_FUNC_GPIO &pcfg_pull_up>;
		};

		pcie0_poweren_gpio: pcie0-poweren-gpio {
			rockchip,pins = <4 RK_PB4 RK_FUNC_GPIO &pcfg_pull_up>;
		};
	};

	wdt {
		wdt_gpio: wdt-gpio {
			rockchip,pins = <0 RK_PC3 RK_FUNC_GPIO &pcfg_pull_none>;
		};
	};
};

&pwm1_6ch_1 {
	status = "okay";
	pinctrl-0 = <&pwm1m0_ch1>;
};

&rga2_core0 {
	status = "okay";
};

&rga2_core0_mmu {
	status = "okay";
};

&rga2_core1 {
	status = "okay";
};

&rga2_core1_mmu {
	status = "okay";
};

&rknpu {
	rknpu-supply = <&vdd_npu_s0>;
	status = "okay";
};

&rknpu_mmu {
	status = "okay";
};

&rkvenc_ccu {
	status = "okay";
};

&rkvenc0 {
	status = "okay";
};

&rkvenc0_mmu {
	status = "okay";
};

&rkvenc1 {
	status = "okay";
};

&rkvenc1_mmu {
	status = "okay";

};

&rkvdec {
	status = "okay";
};

&rkvdec_mmu {
	status = "okay";
};

&rockchip_suspend {
	status = "okay";
	rockchip,sleep-debug-en = <1>;

	rockchip,sleep-io-ret-config = <
		(0
		| RKPM_VCCIO3_RET_EN
		)
	>;

	rockchip,regulator-on-before-mem = <&vdd_npu_s0>;
};

&route_dsi {
	status = "okay";
	connect = <&vp1_out_dsi>;
};

&sai6 {
	status = "okay";
};

&saradc {
	status = "okay";
	vref-supply = <&vcca_1v8_s0>;
};

&sdhci {
	bus-width = <8>;
	no-sdio;
	no-sd;
	non-removable;
	max-frequency = <200000000>;
	mmc-hs400-1_8v;
	mmc-hs400-enhanced-strobe;
	full-pwr-cycle-in-suspend;
	status = "okay";
};

&sdmmc {
	max-frequency = <200000000>;
	no-sdio;
	no-mmc;
	bus-width = <4>;
	cap-mmc-highspeed;
	cap-sd-highspeed;
	disable-wp;
	sd-uhs-sdr104;
	vqmmc-supply = <&vccio_sd_s0>;
	status = "disabled";
};

&tsadc {
	status = "okay";
};

&u2phy0 {
	status = "okay";
};

&u2phy1 {
	status = "okay";
};

&u2phy0_otg {
	status = "okay";
};

&u2phy1_otg {
	status = "okay";
};

&uart5 {
	status = "okay";
	pinctrl-names = "default";
	pinctrl-0 = <&uart5m1_xfer &uart5m1_ctsn>;
};

&ufs {
	reset-gpios = <&gpio4 RK_PD0 GPIO_ACTIVE_HIGH>;
};

&usbdp_phy {
	status = "okay";
};

&usbdp_phy_dp {
	status = "okay";
};

&usbdp_phy_u3 {
	status = "okay";
};

&usb_drd0_dwc3 {
	status = "okay";
};

&vdpp {
	status = "okay";
};

&vop {
	status = "okay";
	vop-supply = <&vdd_logic_s0>;
};

&vop_mmu {
	status = "okay";
};

&vp2 {
	assigned-clocks = <&cru DCLK_VP2_SRC>;
	assigned-clock-parents = <&cru PLL_VPLL>;
};
